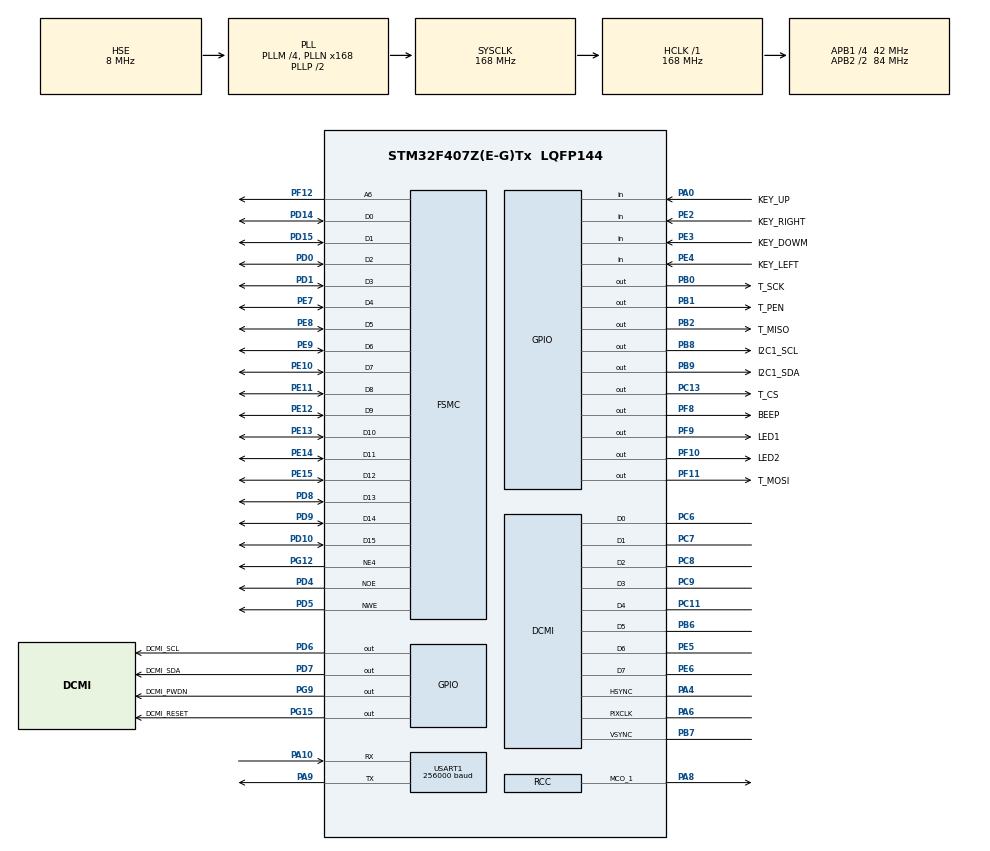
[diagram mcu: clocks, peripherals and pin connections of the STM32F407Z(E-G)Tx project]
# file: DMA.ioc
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DCMI.VSPolarity=DCMI_VSPOLARITY_HIGH
Dma.DCMI.0.Direction=DMA_PERIPH_TO_MEMORY
Dma.DCMI.0.FIFOMode=DMA_FIFOMODE_ENABLE
Dma.DCMI.0.FIFOThreshold=DMA_FIFO_THRESHOLD_FULL
Dma.DCMI.0.Instance=DMA2_Stream1
Dma.DCMI.0.MemBurst=DMA_MBURST_SINGLE
Dma.DCMI.0.MemDataAlignment=DMA_MDATAALIGN_HALFWORD
Dma.DCMI.0.MemInc=DMA_MINC_DISABLE
Dma.DCMI.0.Mode=DMA_CIRCULAR
Dma.DCMI.0.PeriphBurst=DMA_PBURST_SINGLE
Dma.DCMI.0.PeriphDataAlignment=DMA_PDATAALIGN_WORD
Dma.DCMI.0.PeriphInc=DMA_PINC_DISABLE
Dma.DCMI.0.Priority=DMA_PRIORITY_HIGH
Dma.Request0=DCMI
Dma.Request1=USART1_TX
Dma.USART1_TX.1.Direction=DMA_MEMORY_TO_PERIPH
Dma.USART1_TX.1.FIFOMode=DMA_FIFOMODE_DISABLE
Dma.USART1_TX.1.Instance=DMA2_Stream7
Dma.USART1_TX.1.MemDataAlignment=DMA_MDATAALIGN_BYTE
Dma.USART1_TX.1.MemInc=DMA_MINC_ENABLE
Dma.USART1_TX.1.Mode=DMA_NORMAL
Dma.USART1_TX.1.PeriphDataAlignment=DMA_PDATAALIGN_BYTE
Dma.USART1_TX.1.PeriphInc=DMA_PINC_DISABLE
Dma.USART1_TX.1.Priority=DMA_PRIORITY_LOW
FSMC.AddressSetupTime1=15
FSMC.BusTurnAroundDuration1=0
FSMC.DataSetupTime1=15
FSMC.ExtendedAddressSetupTime1=15
FSMC.ExtendedBusTurnAroundDuration1=0
FSMC.ExtendedDataSetupTime1=15
FSMC.ExtendedMode1=FSMC_EXTENDED_MODE_ENABLE
Mcu.Family=STM32F4
Mcu.Name=STM32F407Z(E-G)Tx
Mcu.Package=LQFP144
NVIC.DCMI_IRQn=true\:2\:0\:true\:false\:true\:true\:true
NVIC.DMA2_Stream1_IRQn=true\:0\:0\:false\:false\:true\:false\:true
NVIC.DMA2_Stream7_IRQn=true\:0\:0\:false\:false\:true\:false\:true
NVIC.PriorityGroup=NVIC_PRIORITYGROUP_4
NVIC.TIM7_IRQn=true\:0\:0\:false\:false\:true\:true\:true
NVIC.USART1_IRQn=true\:3\:0\:true\:false\:true\:true\:true
PA0-WKUP.GPIO_Label=KEY_UP
PA0-WKUP.GPIO_PuPd=GPIO_PULLDOWN
PA0-WKUP.Signal=GPIO_Input
PA10.Mode=Asynchronous
PA10.Signal=USART1_RX
PA13.Mode=Serial_Wire
PA13.Signal=SYS_JTMS-SWDIO
PA14.Mode=Serial_Wire
PA14.Signal=SYS_JTCK-SWCLK
PA4.GPIO_PuPd=GPIO_PULLUP
PA4.Mode=Slave_8_bits_External_Synchro
PA4.Signal=DCMI_HSYNC
PA6.GPIO_PuPd=GPIO_PULLUP
PA6.Mode=Slave_8_bits_External_Synchro
PA6.Signal=DCMI_PIXCLK
PA8.Mode=Clock-out-1
PA8.Signal=RCC_MCO_1
PA9.GPIO_PuPd=GPIO_PULLUP
PA9.Mode=Asynchronous
PA9.Signal=USART1_TX
PB0.GPIO_Label=T_SCK
PB0.Signal=GPIO_Output
PB1.GPIO_Label=T_PEN
PB1.Signal=GPIO_Output
PB2.GPIO_Label=T_MISO
PB2.Signal=GPIO_Output
PB6.Mode=Slave_8_bits_External_Synchro
PB6.Signal=DCMI_D5
PB7.Mode=Slave_8_bits_External_Synchro
PB7.Signal=DCMI_VSYNC
PB8.GPIO_Label=I2C1_SCL
PB8.Signal=GPIO_Output
PB9.GPIO_Label=I2C1_SDA
PB9.Signal=GPIO_Output
PC11.Mode=Slave_8_bits_External_Synchro
PC11.Signal=DCMI_D4
PC13-ANTI_TAMP.GPIO_Label=T_CS
PC13-ANTI_TAMP.Signal=GPIO_Output
PC6.Mode=Slave_8_bits_External_Synchro
PC6.Signal=DCMI_D0
PC7.Mode=Slave_8_bits_External_Synchro
PC7.Signal=DCMI_D1
PC8.Mode=Slave_8_bits_External_Synchro
PC8.Signal=DCMI_D2
PC9.Mode=Slave_8_bits_External_Synchro
PC9.Signal=DCMI_D3
PD0.Signal=FSMC_D2_DA2
PD1.Signal=FSMC_D3_DA3
PD10.Signal=FSMC_D15_DA15
PD14.Signal=FSMC_D0_DA0
PD15.Signal=FSMC_D1_DA1
PD4.Signal=FSMC_NOE
PD5.Signal=FSMC_NWE
PD6.GPIO_Label=DCMI_SCL
PD6.GPIO_PuPd=GPIO_PULLUP
PD6.Signal=GPIO_Output
PD7.GPIO_Label=DCMI_SDA
PD7.GPIO_PuPd=GPIO_PULLUP
PD7.Signal=GPIO_Output
PD8.Signal=FSMC_D13_DA13
PD9.Signal=FSMC_D14_DA14
PE10.Signal=FSMC_D7_DA7
PE11.Signal=FSMC_D8_DA8
PE12.Signal=FSMC_D9_DA9
PE13.Signal=FSMC_D10_DA10
PE14.Signal=FSMC_D11_DA11
PE15.Signal=FSMC_D12_DA12
PE2.GPIO_Label=KEY_RIGHT
PE2.GPIO_PuPd=GPIO_PULLUP
PE2.Signal=GPIO_Input
PE3.GPIO_Label=KEY_DOWM
PE3.GPIO_PuPd=GPIO_PULLUP
PE3.Signal=GPIO_Input
PE4.GPIO_Label=KEY_LEFT
PE4.GPIO_PuPd=GPIO_PULLUP
PE4.Signal=GPIO_Input
PE5.Mode=Slave_8_bits_External_Synchro
PE5.Signal=DCMI_D6
PE6.Mode=Slave_8_bits_External_Synchro
PE6.Signal=DCMI_D7
PE7.Signal=FSMC_D4_DA4
PE8.Signal=FSMC_D5_DA5
PE9.Signal=FSMC_D6_DA6
PF10.GPIO_Label=LED2
PF10.GPIO_PuPd=GPIO_PULLUP
PF10.GPIO_Speed=GPIO_SPEED_FREQ_HIGH
PF10.PinState=GPIO_PIN_SET
PF10.Signal=GPIO_Output
PF11.GPIO_Label=T_MOSI
PF11.Signal=GPIO_Output
PF12.Signal=FSMC_A6
PF8.GPIO_Label=BEEP
PF8.GPIO_PuPd=GPIO_PULLUP
PF8.GPIO_Speed=GPIO_SPEED_FREQ_HIGH
PF8.PinState=GPIO_PIN_SET
PF8.Signal=GPIO_Output
PF9.GPIO_Label=LED1
PF9.GPIO_PuPd=GPIO_PULLUP
PF9.GPIO_Speed=GPIO_SPEED_FREQ_HIGH
PF9.PinState=GPIO_PIN_SET
PF9.Signal=GPIO_Output
PG12.Mode=NorPsramChipSelect4_1
PG12.Signal=FSMC_NE4
PG15.GPIO_Label=DCMI_RESET
PG15.GPIO_PuPd=GPIO_PULLUP
PG15.Signal=GPIO_Output
PG9.GPIO_Label=DCMI_PWDN
PG9.GPIO_PuPd=GPIO_PULLUP
PG9.Signal=GPIO_Output
PH0-OSC_IN.Mode=HSE-External-Oscillator
PH0-OSC_IN.Signal=RCC_OSC_IN
PH1-OSC_OUT.Mode=HSE-External-Oscillator
PH1-OSC_OUT.Signal=RCC_OSC_OUT
ProjectManager.HeapSize=0x200
ProjectManager.StackSize=0x400
ProjectManager.TargetToolchain=MDK-ARM V5.27
RCC.48MHZClocksFreq_Value=84000000
RCC.AHBFreq_Value=168000000
RCC.APB1CLKDivider=RCC_HCLK_DIV4
RCC.APB1Freq_Value=42000000
RCC.APB1TimFreq_Value=84000000
RCC.APB2CLKDivider=RCC_HCLK_DIV2
RCC.APB2Freq_Value=84000000
RCC.APB2TimFreq_Value=168000000
RCC.CortexFreq_Value=168000000
RCC.HCLKFreq_Value=168000000
RCC.HSE_VALUE=8000000
RCC.HSI_VALUE=16000000
RCC.LSE_VALUE=32768
RCC.PLLM=4
RCC.PLLN=168
RCC.PLLSourceVirtual=RCC_PLLSOURCE_HSE
RCC.SYSCLKFreq_VALUE=168000000
RCC.SYSCLKSource=RCC_SYSCLKSOURCE_PLLCLK
RCC.VCOOutputFreq_Value=336000000
SH.FSMC_A6.0=FSMC_A6,A6_1
SH.FSMC_D0_DA0.0=FSMC_D0,16b-d1
SH.FSMC_D10_DA10.0=FSMC_D10,16b-d1
SH.FSMC_D11_DA11.0=FSMC_D11,16b-d1
SH.FSMC_D12_DA12.0=FSMC_D12,16b-d1
SH.FSMC_D13_DA13.0=FSMC_D13,16b-d1
SH.FSMC_D14_DA14.0=FSMC_D14,16b-d1
SH.FSMC_D15_DA15.0=FSMC_D15,16b-d1
SH.FSMC_D1_DA1.0=FSMC_D1,16b-d1
SH.FSMC_D2_DA2.0=FSMC_D2,16b-d1
SH.FSMC_D3_DA3.0=FSMC_D3,16b-d1
SH.FSMC_D4_DA4.0=FSMC_D4,16b-d1
SH.FSMC_D5_DA5.0=FSMC_D5,16b-d1
SH.FSMC_D6_DA6.0=FSMC_D6,16b-d1
SH.FSMC_D7_DA7.0=FSMC_D7,16b-d1
SH.FSMC_D8_DA8.0=FSMC_D8,16b-d1
SH.FSMC_D9_DA9.0=FSMC_D9,16b-d1
SH.FSMC_NOE.0=FSMC_NOE,Lcd1
SH.FSMC_NWE.0=FSMC_NWE,Lcd1
USART1.BaudRate=256000
USART1.VirtualMode=VM_ASYNC
VP_TIM7_VS_ClockSourceINT.Mode=Enable_Timer
board=custom

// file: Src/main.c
/* USER CODE BEGIN Header */
/**
  ******************************************************************************
  * @file           : main.c
  * @brief          : Main program body
  ******************************************************************************
  * @attention
  *
  * <h2><center>&copy; Copyright (c) 2019 STMicroelectronics.
  * All rights reserved.</center></h2>
  *
  * This software component is licensed by ST under BSD 3-Clause license,
  * the "License"; You may not use this file except in compliance with the
  * License. You may obtain a copy of the License at:
  *                        opensource.org/licenses/BSD-3-Clause
  *
  ******************************************************************************
  */
/* USER CODE END Header */

#include "main.h"

/* USER CODE BEGIN Includes */
#include "board.h"
#include "LCD.h"
#include "ov7670.h"
#include "SysTick.h"
#include "dcmi.h"
#include "str.h"
/* USER CODE END Includes */

DCMI_HandleTypeDef hdcmi;
DMA_HandleTypeDef hdma_dcmi;

TIM_HandleTypeDef htim7;

UART_HandleTypeDef huart1;
DMA_HandleTypeDef hdma_usart1_tx;

SRAM_HandleTypeDef hsram1;

void SystemClock_Config(void);
static void MX_GPIO_Init(void);
static void MX_USART1_UART_Init(void);
static void MX_FSMC_Init(void);
static void MX_DMA_Init(void);
static void MX_DCMI_Init(void);
static void MX_TIM7_Init(void);

int main(void)
{

  /* MCU Configuration--------------------------------------------------------*/

  /* Reset of all peripherals, Initializes the Flash interface and the Systick. */
  HAL_Init();

  /* Configure the system clock */
  SystemClock_Config();

  /* Initialize all configured peripherals */
  MX_GPIO_Init();
  MX_USART1_UART_Init();
  MX_FSMC_Init();
  MX_DMA_Init();
  MX_DCMI_Init();
  MX_TIM7_Init();
  /* USER CODE BEGIN 2 */
  startManage();

  /* USER CODE END 2 */

  /* Infinite loop */
  /* USER CODE BEGIN WHILE */
  while (1)
  {
       board_quick();

    /* USER CODE END WHILE */

  }
}

void SystemClock_Config(void)
{
  RCC_OscInitTypeDef RCC_OscInitStruct = {0};
  RCC_ClkInitTypeDef RCC_ClkInitStruct = {0};

  /** Configure the main internal regulator output voltage
  */
  __HAL_RCC_PWR_CLK_ENABLE();
  __HAL_PWR_VOLTAGESCALING_CONFIG(PWR_REGULATOR_VOLTAGE_SCALE1);
  /** Initializes the CPU, AHB and APB busses clocks
  */
  RCC_OscInitStruct.OscillatorType = RCC_OSCILLATORTYPE_HSI|RCC_OSCILLATORTYPE_HSE;
  RCC_OscInitStruct.HSEState = RCC_HSE_ON;
  RCC_OscInitStruct.HSIState = RCC_HSI_ON;
  RCC_OscInitStruct.HSICalibrationValue = RCC_HSICALIBRATION_DEFAULT;
  RCC_OscInitStruct.PLL.PLLState = RCC_PLL_ON;
  RCC_OscInitStruct.PLL.PLLSource = RCC_PLLSOURCE_HSE;
  RCC_OscInitStruct.PLL.PLLM = 4;
  RCC_OscInitStruct.PLL.PLLN = 168;
  RCC_OscInitStruct.PLL.PLLP = RCC_PLLP_DIV2;
  RCC_OscInitStruct.PLL.PLLQ = 4;
  if (HAL_RCC_OscConfig(&RCC_OscInitStruct) != HAL_OK)
  {
    Error_Handler();
  }
  /** Initializes the CPU, AHB and APB busses clocks
  */
  RCC_ClkInitStruct.ClockType = RCC_CLOCKTYPE_HCLK|RCC_CLOCKTYPE_SYSCLK
                              |RCC_CLOCKTYPE_PCLK1|RCC_CLOCKTYPE_PCLK2;
  RCC_ClkInitStruct.SYSCLKSource = RCC_SYSCLKSOURCE_PLLCLK;
  RCC_ClkInitStruct.AHBCLKDivider = RCC_SYSCLK_DIV1;
  RCC_ClkInitStruct.APB1CLKDivider = RCC_HCLK_DIV4;
  RCC_ClkInitStruct.APB2CLKDivider = RCC_HCLK_DIV2;

  if (HAL_RCC_ClockConfig(&RCC_ClkInitStruct, FLASH_LATENCY_5) != HAL_OK)
  {
    Error_Handler();
  }
  HAL_RCC_MCOConfig(RCC_MCO1, RCC_MCO1SOURCE_HSI, RCC_MCODIV_1);
}

static void MX_DCMI_Init(void)
{

  hdcmi.Instance = DCMI;
  hdcmi.Init.SynchroMode = DCMI_SYNCHRO_HARDWARE;
  hdcmi.Init.PCKPolarity = DCMI_PCKPOLARITY_FALLING;
  hdcmi.Init.VSPolarity = DCMI_VSPOLARITY_HIGH;
  hdcmi.Init.HSPolarity = DCMI_HSPOLARITY_LOW;
  hdcmi.Init.CaptureRate = DCMI_CR_ALL_FRAME;
  hdcmi.Init.ExtendedDataMode = DCMI_EXTEND_DATA_8B;
  hdcmi.Init.JPEGMode = DCMI_JPEG_DISABLE;
  if (HAL_DCMI_Init(&hdcmi) != HAL_OK)
  {
    Error_Handler();
  }

}

static void MX_TIM7_Init(void)
{

  TIM_MasterConfigTypeDef sMasterConfig = {0};

  htim7.Instance = TIM7;
  htim7.Init.Prescaler = 0;
  htim7.Init.CounterMode = TIM_COUNTERMODE_UP;
  htim7.Init.Period = 0;
  htim7.Init.AutoReloadPreload = TIM_AUTORELOAD_PRELOAD_DISABLE;
  if (HAL_TIM_Base_Init(&htim7) != HAL_OK)
  {
    Error_Handler();
  }
  sMasterConfig.MasterOutputTrigger = TIM_TRGO_RESET;
  sMasterConfig.MasterSlaveMode = TIM_MASTERSLAVEMODE_DISABLE;
  if (HAL_TIMEx_MasterConfigSynchronization(&htim7, &sMasterConfig) != HAL_OK)
  {
    Error_Handler();
  }

}

static void MX_USART1_UART_Init(void)
{

  huart1.Instance = USART1;
  huart1.Init.BaudRate = 256000;
  huart1.Init.WordLength = UART_WORDLENGTH_8B;
  huart1.Init.StopBits = UART_STOPBITS_1;
  huart1.Init.Parity = UART_PARITY_NONE;
  huart1.Init.Mode = UART_MODE_TX_RX;
  huart1.Init.HwFlowCtl = UART_HWCONTROL_NONE;
  huart1.Init.OverSampling = UART_OVERSAMPLING_16;
  if (HAL_UART_Init(&huart1) != HAL_OK)
  {
    Error_Handler();
  }

}

static void MX_DMA_Init(void)
{

  /* DMA controller clock enable */
  __HAL_RCC_DMA2_CLK_ENABLE();

  /* DMA interrupt init */
  /* DMA2_Stream1_IRQn interrupt configuration */
  HAL_NVIC_SetPriority(DMA2_Stream1_IRQn, 0, 0);
  HAL_NVIC_EnableIRQ(DMA2_Stream1_IRQn);
  /* DMA2_Stream7_IRQn interrupt configuration */
  HAL_NVIC_SetPriority(DMA2_Stream7_IRQn, 0, 0);
  HAL_NVIC_EnableIRQ(DMA2_Stream7_IRQn);

}

static void MX_GPIO_Init(void)
{
  GPIO_InitTypeDef GPIO_InitStruct = {0};

  /* GPIO Ports Clock Enable */
  __HAL_RCC_GPIOE_CLK_ENABLE();
  __HAL_RCC_GPIOC_CLK_ENABLE();
  __HAL_RCC_GPIOF_CLK_ENABLE();
  __HAL_RCC_GPIOH_CLK_ENABLE();
  __HAL_RCC_GPIOA_CLK_ENABLE();
  __HAL_RCC_GPIOB_CLK_ENABLE();
  __HAL_RCC_GPIOD_CLK_ENABLE();
  __HAL_RCC_GPIOG_CLK_ENABLE();

  /*Configure GPIO pin Output Level */
  HAL_GPIO_WritePin(T_CS_GPIO_Port, T_CS_Pin, GPIO_PIN_RESET);

  /*Configure GPIO pin Output Level */
  HAL_GPIO_WritePin(GPIOF, BEEP_Pin|LED1_Pin|LED2_Pin, GPIO_PIN_SET);

  /*Configure GPIO pin Output Level */
  HAL_GPIO_WritePin(GPIOB, T_SCK_Pin|T_PEN_Pin|T_MISO_Pin|I2C1_SCL_Pin
                          |I2C1_SDA_Pin, GPIO_PIN_RESET);

  /*Configure GPIO pin Output Level */
  HAL_GPIO_WritePin(T_MOSI_GPIO_Port, T_MOSI_Pin, GPIO_PIN_RESET);

  /*Configure GPIO pin Output Level */
  HAL_GPIO_WritePin(GPIOD, DCMI_SCL_Pin|DCMI_SDA_Pin, GPIO_PIN_RESET);

  /*Configure GPIO pin Output Level */
  HAL_GPIO_WritePin(GPIOG, DCMI_PWDN_Pin|DCMI_RESET_Pin, GPIO_PIN_RESET);

  /*Configure GPIO pins : KEY_RIGHT_Pin KEY_DOWM_Pin KEY_LEFT_Pin */
  GPIO_InitStruct.Pin = KEY_RIGHT_Pin|KEY_DOWM_Pin|KEY_LEFT_Pin;
  GPIO_InitStruct.Mode = GPIO_MODE_INPUT;
  GPIO_InitStruct.Pull = GPIO_PULLUP;
  HAL_GPIO_Init(GPIOE, &GPIO_InitStruct);

  /*Configure GPIO pin : T_CS_Pin */
  GPIO_InitStruct.Pin = T_CS_Pin;
  GPIO_InitStruct.Mode = GPIO_MODE_OUTPUT_PP;
  GPIO_InitStruct.Pull = GPIO_NOPULL;
  GPIO_InitStruct.Speed = GPIO_SPEED_FREQ_LOW;
  HAL_GPIO_Init(T_CS_GPIO_Port, &GPIO_InitStruct);

  /*Configure GPIO pins : BEEP_Pin LED1_Pin LED2_Pin */
  GPIO_InitStruct.Pin = BEEP_Pin|LED1_Pin|LED2_Pin;
  GPIO_InitStruct.Mode = GPIO_MODE_OUTPUT_PP;
  GPIO_InitStruct.Pull = GPIO_PULLUP;
  GPIO_InitStruct.Speed = GPIO_SPEED_FREQ_HIGH;
  HAL_GPIO_Init(GPIOF, &GPIO_InitStruct);

  /*Configure GPIO pin : KEY_UP_Pin */
  GPIO_InitStruct.Pin = KEY_UP_Pin;
  GPIO_InitStruct.Mode = GPIO_MODE_INPUT;
  GPIO_InitStruct.Pull = GPIO_PULLDOWN;
  HAL_GPIO_Init(KEY_UP_GPIO_Port, &GPIO_InitStruct);

  /*Configure GPIO pins : T_SCK_Pin T_PEN_Pin T_MISO_Pin I2C1_SCL_Pin
                           I2C1_SDA_Pin */
  GPIO_InitStruct.Pin = T_SCK_Pin|T_PEN_Pin|T_MISO_Pin|I2C1_SCL_Pin
                          |I2C1_SDA_Pin;
  GPIO_InitStruct.Mode = GPIO_MODE_OUTPUT_PP;
  GPIO_InitStruct.Pull = GPIO_NOPULL;
  GPIO_InitStruct.Speed = GPIO_SPEED_FREQ_LOW;
  HAL_GPIO_Init(GPIOB, &GPIO_InitStruct);

  /*Configure GPIO pin : T_MOSI_Pin */
  GPIO_InitStruct.Pin = T_MOSI_Pin;
  GPIO_InitStruct.Mode = GPIO_MODE_OUTPUT_PP;
  GPIO_InitStruct.Pull = GPIO_NOPULL;
  GPIO_InitStruct.Speed = GPIO_SPEED_FREQ_LOW;
  HAL_GPIO_Init(T_MOSI_GPIO_Port, &GPIO_InitStruct);

  /*Configure GPIO pin : PA8 */
  GPIO_InitStruct.Pin = GPIO_PIN_8;
  GPIO_InitStruct.Mode = GPIO_MODE_AF_PP;
  GPIO_InitStruct.Pull = GPIO_NOPULL;
  GPIO_InitStruct.Speed = GPIO_SPEED_FREQ_LOW;
  GPIO_InitStruct.Alternate = GPIO_AF0_MCO;
  HAL_GPIO_Init(GPIOA, &GPIO_InitStruct);

  /*Configure GPIO pins : DCMI_SCL_Pin DCMI_SDA_Pin */
  GPIO_InitStruct.Pin = DCMI_SCL_Pin|DCMI_SDA_Pin;
  GPIO_InitStruct.Mode = GPIO_MODE_OUTPUT_PP;
  GPIO_InitStruct.Pull = GPIO_PULLUP;
  GPIO_InitStruct.Speed = GPIO_SPEED_FREQ_LOW;
  HAL_GPIO_Init(GPIOD, &GPIO_InitStruct);

  /*Configure GPIO pins : DCMI_PWDN_Pin DCMI_RESET_Pin */
  GPIO_InitStruct.Pin = DCMI_PWDN_Pin|DCMI_RESET_Pin;
  GPIO_InitStruct.Mode = GPIO_MODE_OUTPUT_PP;
  GPIO_InitStruct.Pull = GPIO_PULLUP;
  GPIO_InitStruct.Speed = GPIO_SPEED_FREQ_LOW;
  HAL_GPIO_Init(GPIOG, &GPIO_InitStruct);

}

/* FSMC initialization function */
static void MX_FSMC_Init(void)
{

  FSMC_NORSRAM_TimingTypeDef Timing = {0};
  FSMC_NORSRAM_TimingTypeDef ExtTiming = {0};

  /** Perform the SRAM1 memory initialization sequence
  */
  hsram1.Instance = FSMC_NORSRAM_DEVICE;
  hsram1.Extended = FSMC_NORSRAM_EXTENDED_DEVICE;
  /* hsram1.Init */
  hsram1.Init.NSBank = FSMC_NORSRAM_BANK4;
  hsram1.Init.DataAddressMux = FSMC_DATA_ADDRESS_MUX_DISABLE;
  hsram1.Init.MemoryType = FSMC_MEMORY_TYPE_SRAM;
  hsram1.Init.MemoryDataWidth = FSMC_NORSRAM_MEM_BUS_WIDTH_16;
  hsram1.Init.BurstAccessMode = FSMC_BURST_ACCESS_MODE_DISABLE;
  hsram1.Init.WaitSignalPolarity = FSMC_WAIT_SIGNAL_POLARITY_LOW;
  hsram1.Init.WrapMode = FSMC_WRAP_MODE_DISABLE;
  hsram1.Init.WaitSignalActive = FSMC_WAIT_TIMING_BEFORE_WS;
  hsram1.Init.WriteOperation = FSMC_WRITE_OPERATION_ENABLE;
  hsram1.Init.WaitSignal = FSMC_WAIT_SIGNAL_DISABLE;
  hsram1.Init.ExtendedMode = FSMC_EXTENDED_MODE_ENABLE;
  hsram1.Init.AsynchronousWait = FSMC_ASYNCHRONOUS_WAIT_DISABLE;
  hsram1.Init.WriteBurst = FSMC_WRITE_BURST_DISABLE;
  hsram1.Init.PageSize = FSMC_PAGE_SIZE_NONE;
  /* Timing */
  Timing.AddressSetupTime = 15;
  Timing.AddressHoldTime = 15;
  Timing.DataSetupTime = 15;
  Timing.BusTurnAroundDuration = 0;
  Timing.CLKDivision = 16;
  Timing.DataLatency = 17;
  Timing.AccessMode = FSMC_ACCESS_MODE_A;
  /* ExtTiming */
  ExtTiming.AddressSetupTime = 15;
  ExtTiming.AddressHoldTime = 15;
  ExtTiming.DataSetupTime = 15;
  ExtTiming.BusTurnAroundDuration = 0;
  ExtTiming.CLKDivision = 16;
  ExtTiming.DataLatency = 17;
  ExtTiming.AccessMode = FSMC_ACCESS_MODE_A;

  if (HAL_SRAM_Init(&hsram1, &Timing, &ExtTiming) != HAL_OK)
  {
    Error_Handler( );
  }

}

void Error_Handler(void)
{
}

/************************ (C) COPYRIGHT STMicroelectronics *****END OF FILE****/
